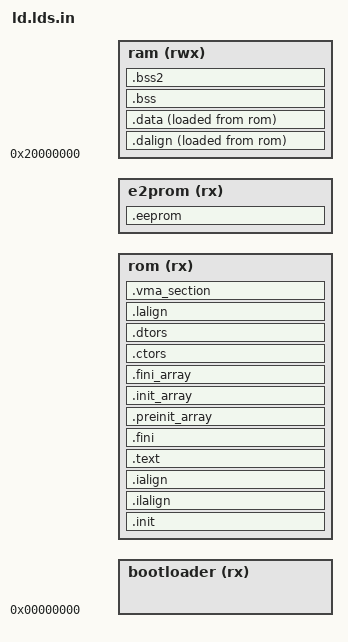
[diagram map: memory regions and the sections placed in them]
OUTPUT_ARCH( "riscv" )

ENTRY( _start )
MEMORY
{
  ram (rwx) :       ORIGIN = 0x20000000, LENGTH = @LN_MCU_RAM_SIZE@K
  bootloader (rx):  ORIGIN = 0x00000000, LENGTH = @LN_BOOTLOADER_SIZE@K
  rom (rx)  :       ORIGIN = 0x00000000+@LN_BOOTLOADER_SIZE@K, LENGTH = @LN_MCU_FLASH_SIZE@K-@LN_MCU_EEPROM_SIZE@K-@LN_BOOTLOADER_SIZE@K
  e2prom (rx)  :    ORIGIN = 0x00000000+@LN_MCU_FLASH_SIZE@K-@LN_MCU_EEPROM_SIZE@K, LENGTH = @LN_MCU_EEPROM_SIZE@K
}

/**
    we allocate 4 kB at the end for the eeprom
*/
PROVIDE(eeprom_size = LENGTH(e2prom));
PROVIDE(eeprom_begin = ORIGIN(e2prom));
REGION_ALIAS("REGION_EEPROM", e2prom);


SECTIONS
{
  __stack_size = DEFINED(__stack_size) ? __stack_size : 512; /* original stack, we dont use it */


  .init           :
  {
    KEEP (*(SORT_NONE(.init)))
  } >rom AT>rom 

  .ilalign         :
  {
    . = ALIGN(4);
    PROVIDE( _ilm_lma = . );
  } >rom AT>rom 

  .ialign         :
  {
    PROVIDE( _ilm = . );
  } >rom AT>rom 

  .text           :
  {
    *(.rodata .rodata.*)  
    *(.text.unlikely .text.unlikely.*)
    *(.text.startup .text.startup.*)
    *(.text .text.*)
    *(.gnu.linkonce.t.*)
  } >rom AT>rom 

  .fini           :
  {
    KEEP (*(SORT_NONE(.fini)))
  } >rom AT>rom 

  . = ALIGN(4);

  PROVIDE (__etext = .);
  PROVIDE (_etext = .);/*0x80022c8*/
  PROVIDE (etext = .);/*0x80022c8*/
  PROVIDE( _eilm = . );

  .preinit_array  :
  {
    PROVIDE_HIDDEN (__preinit_array_start = .);
    KEEP (*(.preinit_array))
    PROVIDE_HIDDEN (__preinit_array_end = .);
  } >rom AT>rom 

  .init_array     :
  {
    PROVIDE_HIDDEN (__init_array_start = .);
    KEEP (*(SORT_BY_INIT_PRIORITY(.init_array.*) SORT_BY_INIT_PRIORITY(.ctors.*)))
    KEEP (*(.init_array EXCLUDE_FILE (*crtbegin.o *crtbegin?.o *crtend.o *crtend?.o ) .ctors))
    PROVIDE_HIDDEN (__init_array_end = .);
  } >rom AT>rom 

  .fini_array     :
  {
    PROVIDE_HIDDEN (__fini_array_start = .);
    KEEP (*(SORT_BY_INIT_PRIORITY(.fini_array.*) SORT_BY_INIT_PRIORITY(.dtors.*)))
    KEEP (*(.fini_array EXCLUDE_FILE (*crtbegin.o *crtbegin?.o *crtend.o *crtend?.o ) .dtors))
    PROVIDE_HIDDEN (__fini_array_end = .);
  } >rom AT>rom 

  .ctors          :
  {
    /* gcc uses crtbegin.o to find the start of
       the constructors, so we make sure it is
       first.  Because this is a wildcard, it
       doesn't matter if the user does not
       actually link against crtbegin.o; the
       linker won't look for a file to match a
       wildcard.  The wildcard also means that it
       doesn't matter which directory crtbegin.o
       is in.  */
    KEEP (*crtbegin.o(.ctors))
    KEEP (*crtbegin?.o(.ctors))
    /* We don't want to include the .ctor section from
       the crtend.o file until after the sorted ctors.
       The .ctor section from the crtend file contains the
       end of ctors marker and it must be last */
    KEEP (*(EXCLUDE_FILE (*crtend.o *crtend?.o ) .ctors))
    KEEP (*(SORT(.ctors.*)))
    KEEP (*(.ctors))
  } >rom AT>rom 

  .dtors          :
  {
    KEEP (*crtbegin.o(.dtors))
    KEEP (*crtbegin?.o(.dtors))
    KEEP (*(EXCLUDE_FILE (*crtend.o *crtend?.o ) .dtors))
    KEEP (*(SORT(.dtors.*)))
    KEEP (*(.dtors))
  } >rom AT>rom 

    . = ALIGN(4);
    PROVIDE( _eilm = . );

  .lalign         :
  {
    . = ALIGN(4);
    PROVIDE( _data_lma = . );
  } >rom AT>rom 
 
  .dalign         :
  {
    . = ALIGN(4);
    PROVIDE( _data = . );
  } >ram AT>rom 
  
  
  .vma_section : 
  {
    . = ALIGN(4);
    PROVIDE( _data_lma = .);
  } > rom
  .data          :
  {
    PROVIDE( _data_begin = .);
    *(.rdata) 
   
    *(.gnu.linkonce.r.*)
    *(.data .data.*)
    *(.gnu.linkonce.d.*)
    . = ALIGN(8);
    PROVIDE( __global_pointer$ = . + 0x800); 
    *(.sdata .sdata.*)
    *(.gnu.linkonce.s.*)
    . = ALIGN(8);
    *(.srodata.cst16)
    *(.srodata.cst8)
    *(.srodata.cst4)
    *(.srodata.cst2)
    *(.srodata .srodata.*)
    PROVIDE( _data_end = .); 
  } >ram AT>rom 
  
  .bss            (NOLOAD) :
  {
    . = ALIGN(4);
    PROVIDE( _bss_begin = . );
    *(.sbss*)
    *(.gnu.linkonce.sb.*)
    *(.bss .bss.*)
    *(.gnu.linkonce.b.*)
    *(COMMON)
   } > ram AT>ram 
   .bss2 (NOLOAD) : 
   {
    *(.initial_heap) /* actually total heap size */
    . = ALIGN(4);
    PROVIDE(_bss_end = .);
    } >ram AT>ram 

  . = ALIGN(8);
  PROVIDE( _end = . ); /*0X2000,0340*/
  PROVIDE( end = . );


  .eeprom eeprom_begin :
      {
        . = eeprom_size;
      } > REGION_EEPROM AT > REGION_EEPROM

}
